AUTOSAR XML (schema 4-0-3)
standard types defined: Boolean, UInt16, UInt32, UInt8
package /AUTOSAR_Platform/DataConstrs
  range DC_Boolean: raw 0..1
  range DC_UInt16: raw 0..65535
  range DC_UInt8: raw 0..255
package /PATAC/MSM/ComponentTypes
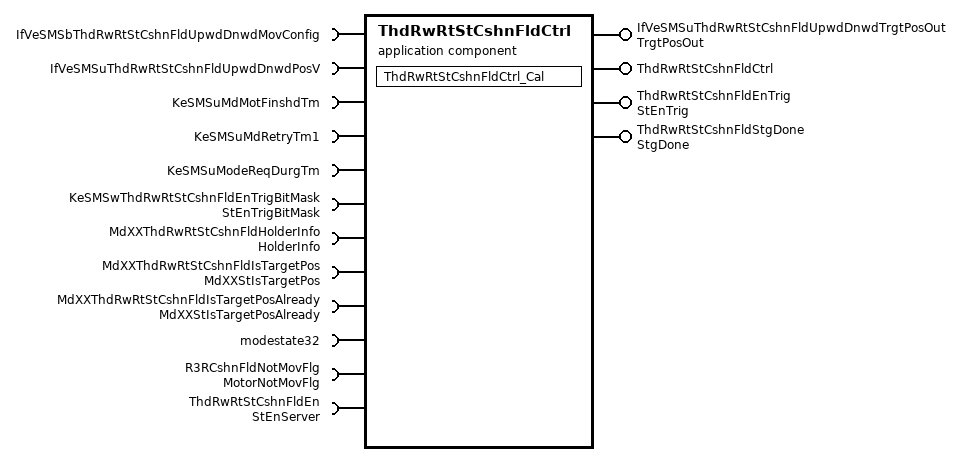
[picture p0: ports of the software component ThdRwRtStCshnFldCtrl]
  application sw component type ThdRwRtStCshnFldCtrl
    4 x provide port:
      IfVeSMSuThdRwRtStCshnFldUpwdDnwdTrgtPosOut: nonqueued-sender-com-spec{data-element=TrgtPosOut/Val, init-value=0}, provided-interface=TrgtPosOut
      ThdRwRtStCshnFldCtrl: server-com-spec{operation=Cal, queue-length=1}, provided-interface=ThdRwRtStCshnFldCtrl
      ThdRwRtStCshnFldEnTrig: nonqueued-sender-com-spec{data-element=StEnTrig/Val, init-value=0}, provided-interface=StEnTrig
      ThdRwRtStCshnFldStgDone: nonqueued-sender-com-spec{data-element=StgDone/Val, init-value=0}, provided-interface=StgDone
    12 x require port:
      IfVeSMSbThdRwRtStCshnFldUpwdDnwdMovConfig: nonqueued-receiver-com-spec{data-element=IfVeSMSbThdRwRtStCshnFldUpwdDnwdMovConfig/Val, filter=data-filter-type=ALWAYS, init-value=0}, required-interface=IfVeSMSbThdRwRtStCshnFldUpwdDnwdMovConfig
      IfVeSMSuThdRwRtStCshnFldUpwdDnwdPosV: nonqueued-receiver-com-spec{data-element=IfVeSMSuThdRwRtStCshnFldUpwdDnwdPosV/Val, filter=data-filter-type=ALWAYS, init-value=0}, required-interface=IfVeSMSuThdRwRtStCshnFldUpwdDnwdPosV
      KeSMSuMdMotFinshdTm: parameter-require-com-spec{init-value=0, parameter=KeSMSuMdMotFinshdTm/Val}, required-interface=KeSMSuMdMotFinshdTm
      KeSMSuMdRetryTm1: parameter-require-com-spec{init-value=0, parameter=KeSMSuMdRetryTm1/Val}, required-interface=KeSMSuMdRetryTm1
      KeSMSuModeReqDurgTm: parameter-require-com-spec{init-value=0, parameter=KeSMSuModeReqDurgTm/Val}, required-interface=KeSMSuModeReqDurgTm
      KeSMSwThdRwRtStCshnFldEnTrigBitMask: parameter-require-com-spec{init-value=6153, parameter=StEnTrigBitMask/Val}, required-interface=StEnTrigBitMask
      MdXXThdRwRtStCshnFldHolderInfo: nonqueued-receiver-com-spec{data-element=HolderInfo/Val, filter=data-filter-type=ALWAYS, init-value=0}, required-interface=HolderInfo
      MdXXThdRwRtStCshnFldIsTargetPos: nonqueued-receiver-com-spec{data-element=MdXXStIsTargetPos/Val, filter=data-filter-type=ALWAYS, init-value=0}, required-interface=MdXXStIsTargetPos
      MdXXThdRwRtStCshnFldIsTargetPosAlready: nonqueued-receiver-com-spec{data-element=MdXXStIsTargetPosAlready/Val, filter=data-filter-type=ALWAYS, init-value=0}, required-interface=MdXXStIsTargetPosAlready
      modestate32: nonqueued-receiver-com-spec{data-element=modestate32/Val, filter=data-filter-type=ALWAYS, init-value=0}, required-interface=modestate32
      R3RCshnFldNotMovFlg: nonqueued-receiver-com-spec{data-element=MotorNotMovFlg/Val, filter=data-filter-type=ALWAYS, init-value=0}, required-interface=MotorNotMovFlg
      ThdRwRtStCshnFldEn: required-com-specs=[Clear, Get, Set], required-interface=StEnServer
    behavior ThdRwRtStCshnFldCtrl_InternalBehavior
      operation invoked event OIT_ThdRwRtStCshnFldCtrl_Cal_ThdRwRtStCshnFldCtrl_Cal: start-on-event=ThdRwRtStCshnFldCtrl_Cal, operation=ThdRwRtStCshnFldCtrl.Cal
      runnable ThdRwRtStCshnFldCtrl_Cal
        data-receive-point-by-arguments:
          7 x access:
            REC_IfVeSMSbThdRwRtStCshnFldUpwdDnwdMovConfig_Val: accessed-variable=IfVeSMSbThdRwRtStCshnFldUpwdDnwdMovConfig.Val
            REC_IfVeSMSuThdRwRtStCshnFldUpwdDnwdPosV_Val: accessed-variable=IfVeSMSuThdRwRtStCshnFldUpwdDnwdPosV.Val
            REC_MdXXThdRwRtStCshnFldHolderInfo_Val: accessed-variable=MdXXThdRwRtStCshnFldHolderInfo.Val
            REC_MdXXThdRwRtStCshnFldIsTargetPos_Val: accessed-variable=MdXXThdRwRtStCshnFldIsTargetPos.Val
            REC_MdXXThdRwRtStCshnFldIsTargetPosAlready_Val: accessed-variable=MdXXThdRwRtStCshnFldIsTargetPosAlready.Val
            REC_modestate32_Val: accessed-variable=modestate32.Val
            REC_R3RCshnFldNotMovFlg_Val: accessed-variable=R3RCshnFldNotMovFlg.Val
        data-send-points:
          access SEND_IfVeSMSuThdRwRtStCshnFldUpwdDnwdTrgtPosOut_Val: accessed-variable=IfVeSMSuThdRwRtStCshnFldUpwdDnwdTrgtPosOut.Val
          access SEND_ThdRwRtStCshnFldEnTrig_Val: accessed-variable=ThdRwRtStCshnFldEnTrig.Val
          access SEND_ThdRwRtStCshnFldStgDone_Val: accessed-variable=ThdRwRtStCshnFldStgDone.Val
        4 x parameter access:
          PA_KeSMSuMdMotFinshdTm_Val: accessed-parameter=KeSMSuMdMotFinshdTm.Val
          PA_KeSMSuMdRetryTm1_Val: accessed-parameter=KeSMSuMdRetryTm1.Val
          PA_KeSMSuModeReqDurgTm_Val: accessed-parameter=KeSMSuModeReqDurgTm.Val
          PA_KeSMSwThdRwRtStCshnFldEnTrigBitMask_Val: accessed-parameter=KeSMSwThdRwRtStCshnFldEnTrigBitMask.Val
        sync call SC_ThdRwRtStCshnFldEn_Get: operation=ThdRwRtStCshnFldEn.Get, timeout=0
  swc implementation ThdRwRtStCshnFldCtrl_Implementation: behavior=ThdRwRtStCshnFldCtrl_InternalBehavior
    code-descriptors:
      code Default: artifact-descriptors=autosar-engineering-object={short-label=Default, category=SWSRC}
package /PATAC/MSM/ModeAdjust/CalPortInterface
  parameter interface KeSMSuMdMotFinshdTm
    parameter data prototype Val: sw-calibration-access=READ-WRITE, type=UInt16
  parameter interface KeSMSuModeReqDurgTm
    parameter data prototype Val: sw-calibration-access=READ-WRITE, type=UInt16
  parameter interface StEnTrigBitMask
    parameter data prototype Val: sw-calibration-access=READ-WRITE, type=UInt32
package /PATAC/MSM/ModeAdjust/Interfaces
  sender receiver interface IfVeSMSuThdRwRtStCshnFldUpwdDnwdPosV: invalidation-policy{data-element=IfVeSMSuThdRwRtStCshnFldUpwdDnwdPosV/Val, handle-invalid=DONT-INVALIDATE}
    data Val: type=Boolean
package /PATAC/MSM/ModeAdjust/PortInterface
  client server interface StEnServer
    operation Clear
      arg data: type=UInt8, direction=IN, server-argument-impl-policy=USE-ARGUMENT-TYPE
    operation Get
      arg data: type=UInt32, direction=OUT, server-argument-impl-policy=USE-ARGUMENT-TYPE
    operation Set
      arg data: type=UInt8, direction=IN, server-argument-impl-policy=USE-ARGUMENT-TYPE
  client server interface ThdRwRtStCshnFldCtrl
    operation Cal
  8 x sender receiver interface:
    HolderInfo: invalidation-policy{data-element=HolderInfo/Val, handle-invalid=DONT-INVALIDATE}
      data Val: type=UInt32
    MdXXStIsTargetPos: invalidation-policy{data-element=MdXXStIsTargetPos/Val, handle-invalid=DONT-INVALIDATE}
      data Val: type=UInt32
    MdXXStIsTargetPosAlready: invalidation-policy{data-element=MdXXStIsTargetPosAlready/Val, handle-invalid=DONT-INVALIDATE}
      data Val: type=UInt32
    modestate32: invalidation-policy{data-element=modestate32/Val, handle-invalid=DONT-INVALIDATE}
      data Val: type=UInt32
    MotorNotMovFlg: invalidation-policy{data-element=MotorNotMovFlg/Val, handle-invalid=DONT-INVALIDATE}
      data Val: type=Boolean
    StEnTrig: invalidation-policy{data-element=StEnTrig/Val, handle-invalid=DONT-INVALIDATE}
      data Val: type=Boolean
    StgDone: invalidation-policy{data-element=StgDone/Val, handle-invalid=DONT-INVALIDATE}
      data Val: type=Boolean
    TrgtPosOut: invalidation-policy{data-element=TrgtPosOut/Val, handle-invalid=DONT-INVALIDATE}
      data Val: type=Boolean
package /PATAC/MSM/PortInterfaces
  parameter interface KeSMSuMdRetryTm1
    parameter data prototype Val: sw-calibration-access=READ-WRITE, type=UInt8
  sender receiver interface IfVeSMSbThdRwRtStCshnFldUpwdDnwdMovConfig: invalidation-policy{data-element=IfVeSMSbThdRwRtStCshnFldUpwdDnwdMovConfig/Val, handle-invalid=DONT-INVALIDATE}
    data Val: type=Boolean
